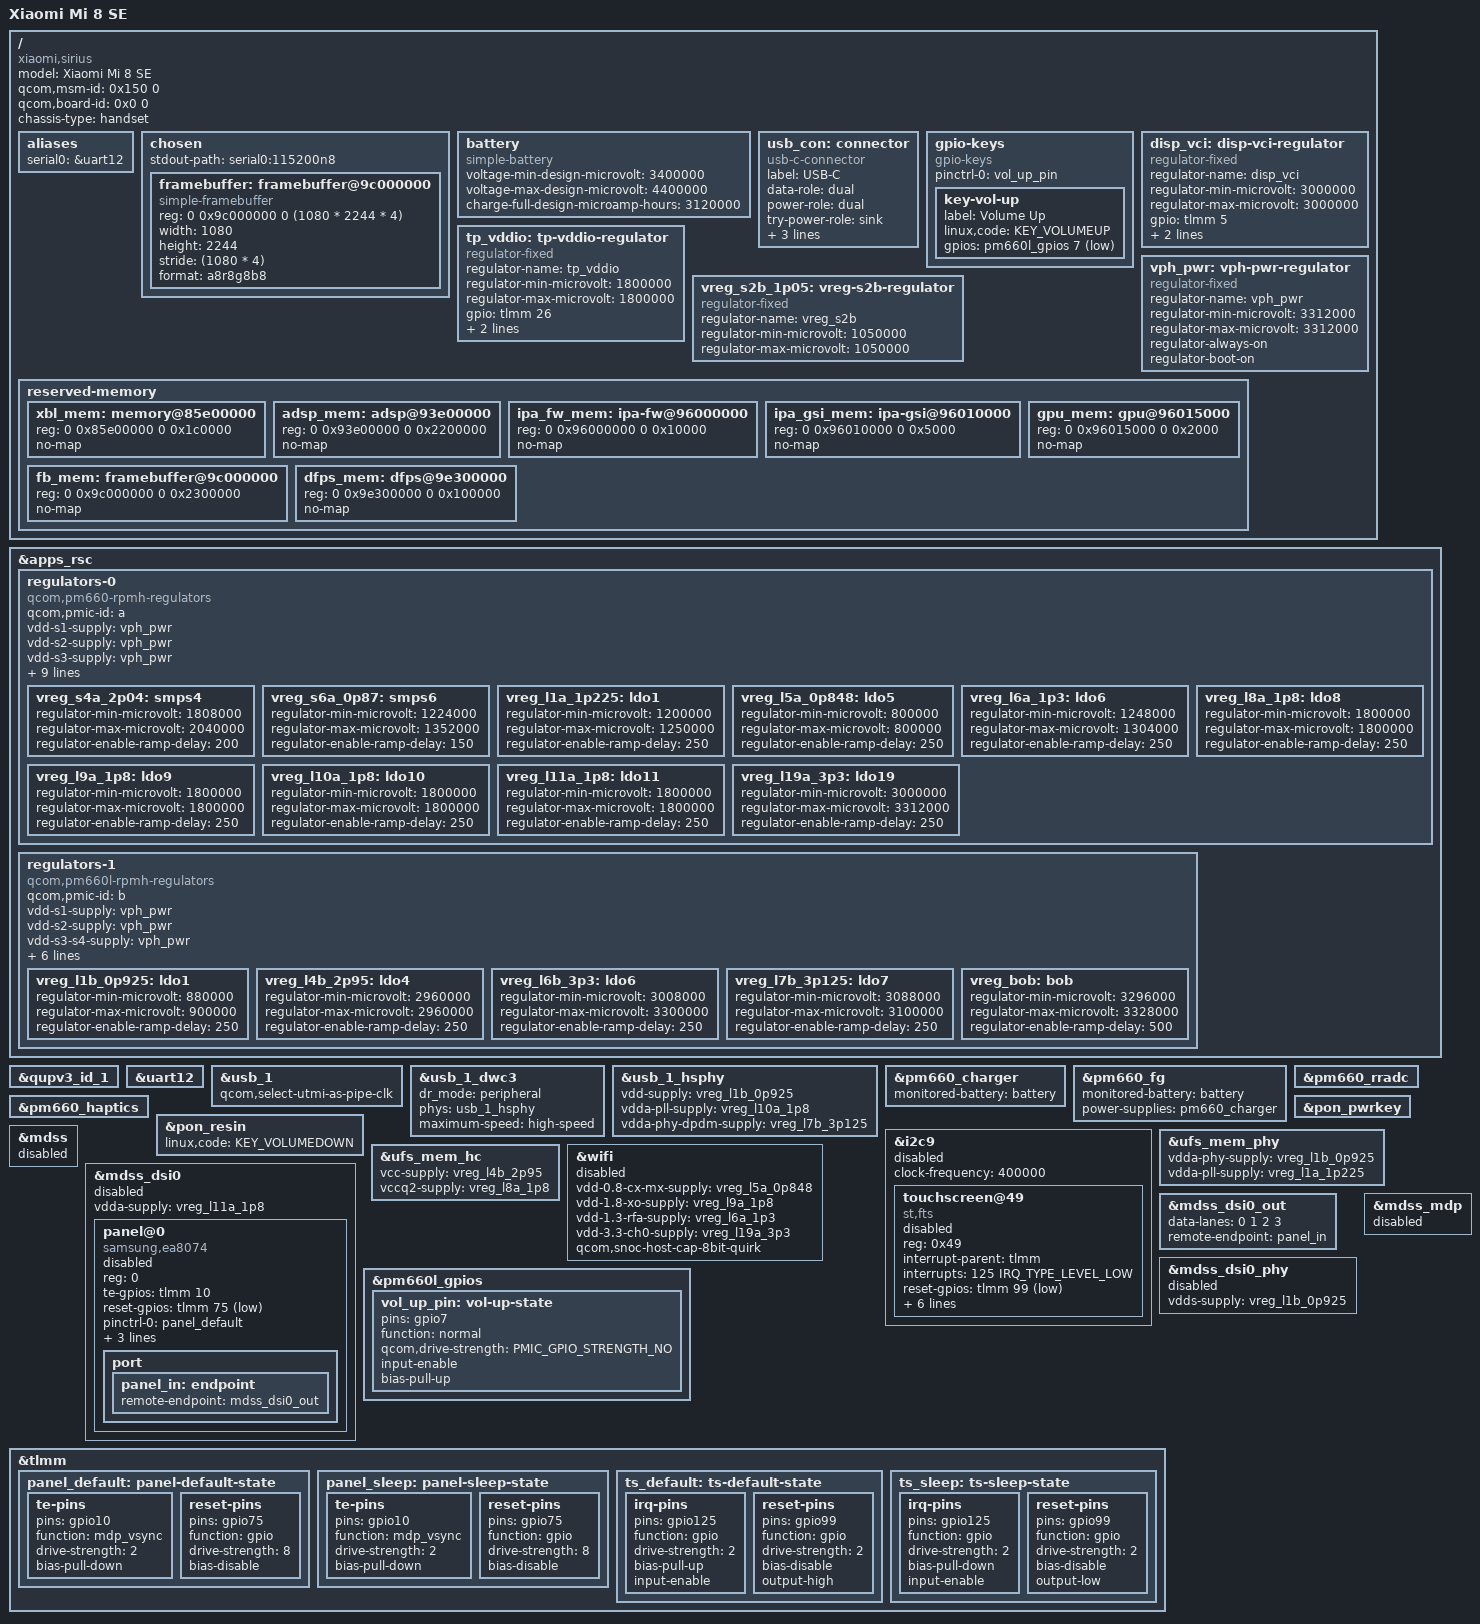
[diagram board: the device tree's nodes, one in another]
// SPDX-License-Identifier: GPL-2.0
/*
 * Xiaomi Mi 8 SE (sirius / xmsirius), SDM710.
 *
 * First board pass: reserved-memory from this unit's live Android DT
 * (2026-08-28), debug UART at 0xA90000, USB2 gadget on a600000.dwc3,
 * PM660 charger + fuel gauge, USB-C connector from this unit's PD caps.
 * No pyxis USB-ID GPIO 38.
 *
 * SMB1355 sits on i2c@a88000 (mainline i2c10) as the Android parallel
 * charger. The shared sdm670-mainline tree has no SMB1355 driver;
 * do not invent a node for it.
 *
 * Display: simple-framebuffer for first boot. Samsung EA8074
 * 1080x2244 command-mode panel driver is in kernel/panel-samsung-ea8074.c
 * (this phone's Android init, not the Mi 8 2248 notch sequence).
 * MDSS/DSI nodes stay disabled until USB enumerates — do not bind
 * samsung,ea8076.
 *
 * UFS uses this phone's Xiaomi 710 supplies (VCCQ2 is PM660 L8 at
 * 1.8 V, not pyxis PM660L L8 at 3.3 V). No UFS reset GPIO in the
 * live Android DT.
 *
 * Wi-Fi supplies are filled; &wifi and remoteproc stay disabled
 * until USB enumerates on hardware. Do not use pyxis board-2.bin.
 */

/dts-v1/;

#include <dt-bindings/gpio/gpio.h>
#include <dt-bindings/input/input.h>
#include <dt-bindings/interrupt-controller/irq.h>
#include <dt-bindings/pinctrl/qcom,pmic-gpio.h>
#include <dt-bindings/power/qcom-rpmpd.h>
#include <dt-bindings/usb/pd.h>
#include "sdm710.dtsi"
#include "pm660.dtsi"
#include "pm660l.dtsi"

/delete-node/ &xbl_mem;
/delete-node/ &adsp_mem;
/delete-node/ &ipa_fw_mem;
/delete-node/ &ipa_gsi_mem;
/delete-node/ &gpu_mem;

/ {
	model = "Xiaomi Mi 8 SE";
	compatible = "xiaomi,sirius", "qcom,sdm710";
	/* Must match this phone's stock boot.img base DTB (ABL match),
	 * not the live Android tree after dtbo overlays (0x168 / 0x20).
	 */
	qcom,msm-id = <0x150 0>;
	qcom,board-id = <0x0 0>;
	chassis-type = "handset";

	aliases {
		serial0 = &uart12;
	};

	chosen {
		stdout-path = "serial0:115200n8";
		#address-cells = <2>;
		#size-cells = <2>;
		ranges;

		/* Live Android 2026-08-28: Physical size 1080x2244.
		 * Only useful if firmware left a splash in fb_mem.
		 * Keep console on serial0 — do not switch stdout here.
		 */
		framebuffer: framebuffer@9c000000 {
			compatible = "simple-framebuffer";
			reg = <0 0x9c000000 0 (1080 * 2244 * 4)>;
			width = <1080>;
			height = <2244>;
			stride = <(1080 * 4)>;
			format = "a8r8g8b8";
		};
	};

	/* Live Android sysfs 2026-08-28: charge_full_design=3120000,
	 * voltage_max=4400000, bms BATTERY_TYPE=e2_atl, Li-poly.
	 * Fuel-gauge cutoff in the live DT is 3400 mV.
	 */
	battery: battery {
		compatible = "simple-battery";
		voltage-min-design-microvolt = <3400000>;
		voltage-max-design-microvolt = <4400000>;
		charge-full-design-microamp-hours = <3120000>;
	};

	/*
	 * Type-C receptacle on this phone. CC / PD silicon (live Android):
	 *   usb-chgpth@1300  interrupt type-c-change
	 *   usb-pdphy@1700   compatible qcom,qpnp-pdphy
	 *                    irqs sig-tx/rx, msg-tx/rx, msg-tx-failed,
	 *                    msg-tx-discarded, msg-rx-discarded
	 *   vdd-pdphy        PM660L L7 (same rail as vreg_l7b_3p125)
	 *   vbus / vconn     smb2-vbus / smb2-vconn on qpnp-smb2
	 *   sink caps        5 V / 3 A and 9 V / 3 A
	 *
	 * Shared sdm670-v7.1.3 TYPEC_QCOM_PMIC only matches pm8150b.
	 * Do not bind that compatible onto PM660, and do not add
	 * usb-role-switch on dwc3 until a real PM660 TCPM exists
	 * (gadget enumeration would wait forever).
	 */
	usb_con: connector {
		compatible = "usb-c-connector";
		label = "USB-C";
		data-role = "dual";
		power-role = "dual";
		try-power-role = "sink";
		sink-pdos = <PDO_FIXED(5000, 3000, PDO_FIXED_USB_COMM)
			     PDO_FIXED(9000, 3000, 0)>;
		op-sink-microwatt = <15000000>;
	};

	/* Same PM660L GPIO 7 as this unit's Android gpio-keys. */
	gpio-keys {
		compatible = "gpio-keys";
		pinctrl-names = "default";
		pinctrl-0 = <&vol_up_pin>;

		key-vol-up {
			label = "Volume Up";
			linux,code = <KEY_VOLUMEUP>;
			gpios = <&pm660l_gpios 7 GPIO_ACTIVE_LOW>;
		};
	};

	/* Panel VCI: TLMM GPIO 5, Android disp_vci_vreg, 3.0 V. */
	disp_vci: disp-vci-regulator {
		compatible = "regulator-fixed";
		regulator-name = "disp_vci";
		regulator-min-microvolt = <3000000>;
		regulator-max-microvolt = <3000000>;
		gpio = <&tlmm 5 GPIO_ACTIVE_HIGH>;
		enable-active-high;
		startup-delay-us = <10000>;
	};

	/* Touch IO: TLMM GPIO 26, Android tp_vddio_vreg. */
	tp_vddio: tp-vddio-regulator {
		compatible = "regulator-fixed";
		regulator-name = "tp_vddio";
		regulator-min-microvolt = <1800000>;
		regulator-max-microvolt = <1800000>;
		gpio = <&tlmm 26 GPIO_ACTIVE_HIGH>;
		enable-active-high;
		startup-delay-us = <4000>;
	};

	vph_pwr: vph-pwr-regulator {
		compatible = "regulator-fixed";
		regulator-name = "vph_pwr";
		regulator-min-microvolt = <3312000>;
		regulator-max-microvolt = <3312000>;
		regulator-always-on;
		regulator-boot-on;
	};

	/* Parent of PM660L L1 / USB PHY vdd. Same PMIC family as pyxis. */
	vreg_s2b_1p05: vreg-s2b-regulator {
		compatible = "regulator-fixed";
		regulator-name = "vreg_s2b";
		regulator-min-microvolt = <1050000>;
		regulator-max-microvolt = <1050000>;
	};

	reserved-memory {
		#address-cells = <2>;
		#size-cells = <2>;

		/*
		 * hyp_mem, camera_mem, and mpss already exist in sdm670.dtsi
		 * at this phone's live addresses. Do not redeclare those
		 * labels. Only replace nodes whose size or base differs.
		 */
		xbl_mem: memory@85e00000 {
			reg = <0 0x85e00000 0 0x1c0000>;
			no-map;
		};

		/*
		 * Android's removed@85fc0000 is the same physical hole as
		 * SoC aop / cmd-db / smem / tz (ends at 0x88f00000 = rmtfs).
		 * Do not re-add it, and do not delete &rmtfs_mem: this
		 * phone does not relocate rmtfs the way pyxis does.
		 * wlan_msa / cdsp / mba already match the SoC file.
		 */
		adsp_mem: adsp@93e00000 {
			reg = <0 0x93e00000 0 0x2200000>;
			no-map;
		};

		ipa_fw_mem: ipa-fw@96000000 {
			reg = <0 0x96000000 0 0x10000>;
			no-map;
		};

		ipa_gsi_mem: ipa-gsi@96010000 {
			reg = <0 0x96010000 0 0x5000>;
			no-map;
		};

		gpu_mem: gpu@96015000 {
			reg = <0 0x96015000 0 0x2000>;
			no-map;
		};

		fb_mem: framebuffer@9c000000 {
			reg = <0 0x9c000000 0 0x2300000>;
			no-map;
		};

		/* Live Android 2026-08-28: between splash and SoC qseecom. */
		dfps_mem: dfps@9e300000 {
			reg = <0 0x9e300000 0 0x100000>;
			no-map;
		};
	};
};

/* RPMH rails needed so the USB PHY supplies exist. Voltages follow
 * the shared PM660 / PM660L map used on pyxis; unused consumers stay off.
 */
&apps_rsc {
	regulators-0 {
		compatible = "qcom,pm660-rpmh-regulators";
		qcom,pmic-id = "a";

		vdd-s1-supply = <&vph_pwr>;
		vdd-s2-supply = <&vph_pwr>;
		vdd-s3-supply = <&vph_pwr>;
		vdd-s4-supply = <&vph_pwr>;
		vdd-s5-supply = <&vph_pwr>;
		vdd-s6-supply = <&vph_pwr>;

		vdd-l1-l6-l7-supply = <&vreg_s6a_0p87>;
		vdd-l2-l3-supply = <&vreg_s2b_1p05>;
		vdd-l5-supply = <&vreg_s2b_1p05>;
		vdd-l8-l9-l10-l11-l12-l13-l14-supply = <&vreg_s4a_2p04>;
		vdd-l15-l16-l17-l18-l19-supply = <&vreg_bob>;

		vreg_s4a_2p04: smps4 {
			regulator-min-microvolt = <1808000>;
			regulator-max-microvolt = <2040000>;
			regulator-enable-ramp-delay = <200>;
		};

		vreg_s6a_0p87: smps6 {
			regulator-min-microvolt = <1224000>;
			regulator-max-microvolt = <1352000>;
			regulator-enable-ramp-delay = <150>;
		};

		vreg_l1a_1p225: ldo1 {
			regulator-min-microvolt = <1200000>;
			regulator-max-microvolt = <1250000>;
			regulator-enable-ramp-delay = <250>;
		};

		vreg_l5a_0p848: ldo5 {
			regulator-min-microvolt = <800000>;
			regulator-max-microvolt = <800000>;
			regulator-enable-ramp-delay = <250>;
		};

		vreg_l6a_1p3: ldo6 {
			regulator-min-microvolt = <1248000>;
			regulator-max-microvolt = <1304000>;
			regulator-enable-ramp-delay = <250>;
		};

		vreg_l8a_1p8: ldo8 {
			regulator-min-microvolt = <1800000>;
			regulator-max-microvolt = <1800000>;
			regulator-enable-ramp-delay = <250>;
		};

		vreg_l9a_1p8: ldo9 {
			regulator-min-microvolt = <1800000>;
			regulator-max-microvolt = <1800000>;
			regulator-enable-ramp-delay = <250>;
		};

		vreg_l10a_1p8: ldo10 {
			regulator-min-microvolt = <1800000>;
			regulator-max-microvolt = <1800000>;
			regulator-enable-ramp-delay = <250>;
		};

		vreg_l11a_1p8: ldo11 {
			regulator-min-microvolt = <1800000>;
			regulator-max-microvolt = <1800000>;
			regulator-enable-ramp-delay = <250>;
		};

		vreg_l19a_3p3: ldo19 {
			regulator-min-microvolt = <3000000>;
			regulator-max-microvolt = <3312000>;
			regulator-enable-ramp-delay = <250>;
		};
	};

	regulators-1 {
		compatible = "qcom,pm660l-rpmh-regulators";
		qcom,pmic-id = "b";

		vdd-s1-supply = <&vph_pwr>;
		vdd-s2-supply = <&vph_pwr>;
		vdd-s3-s4-supply = <&vph_pwr>;
		vdd-s5-supply = <&vph_pwr>;

		vdd-l1-l9-l10-supply = <&vreg_s2b_1p05>;
		vdd-l2-supply = <&vreg_bob>;
		vdd-l3-l5-l7-l8-supply = <&vreg_bob>;
		vdd-l4-l6-supply = <&vreg_bob>;
		vdd-bob-supply = <&vph_pwr>;

		vreg_l1b_0p925: ldo1 {
			regulator-min-microvolt = <880000>;
			regulator-max-microvolt = <900000>;
			regulator-enable-ramp-delay = <250>;
		};

		vreg_l4b_2p95: ldo4 {
			regulator-min-microvolt = <2960000>;
			regulator-max-microvolt = <2960000>;
			regulator-enable-ramp-delay = <250>;
		};

		vreg_l6b_3p3: ldo6 {
			regulator-min-microvolt = <3008000>;
			regulator-max-microvolt = <3300000>;
			regulator-enable-ramp-delay = <250>;
		};

		vreg_l7b_3p125: ldo7 {
			regulator-min-microvolt = <3088000>;
			regulator-max-microvolt = <3100000>;
			regulator-enable-ramp-delay = <250>;
		};

		vreg_bob: bob {
			regulator-min-microvolt = <3296000>;
			regulator-max-microvolt = <3328000>;
			regulator-enable-ramp-delay = <500>;
		};
	};
};

&qupv3_id_1 {
	status = "okay";
};

/* earlycon=msm_geni_serial,0xA90000 on this unit */
&uart12 {
	status = "okay";
};

/* USB2 only — Android DT sets dwc3 maximum-speed = high-speed. */
&usb_1 {
	status = "okay";
	qcom,select-utmi-as-pipe-clk;
};

&usb_1_dwc3 {
	dr_mode = "peripheral";
	phys = <&usb_1_hsphy>;
	phy-names = "usb2-phy";
	maximum-speed = "high-speed";

	/delete-property/ snps,dis_u2_susphy_quirk;
	/delete-property/ snps,dis_enblslpm_quirk;
};

&usb_1_hsphy {
	status = "okay";
	vdd-supply = <&vreg_l1b_0p925>;
	vdda-pll-supply = <&vreg_l10a_1p8>;
	vdda-phy-dpdm-supply = <&vreg_l7b_3p125>;
};

/* Mainline qcom,pm660-charger / qcom,pmi8998-fg. Do not copy
 * Android qpnp-smb2 properties (fcc-max-ua and friends).
 */
&pm660_charger {
	monitored-battery = <&battery>;
	status = "okay";
};

&pm660_fg {
	monitored-battery = <&battery>;
	power-supplies = <&pm660_charger>;
	status = "okay";
};

&pm660_rradc {
	status = "okay";
};

&pm660_haptics {
	status = "okay";
};

&pon_pwrkey {
	status = "okay";
};

&pon_resin {
	linux,code = <KEY_VOLUMEDOWN>;
	status = "okay";
};

/* Touch: live compatible st,fts @ i2c 0xa84000 addr 0x49.
 * Keep the bus off until USB works and st_fts_v521.ftb is packaged.
 */
&i2c9 {
	status = "disabled";
	clock-frequency = <400000>;

	touchscreen@49 {
		compatible = "st,fts";
		reg = <0x49>;
		interrupt-parent = <&tlmm>;
		interrupts = <125 IRQ_TYPE_LEVEL_LOW>;
		reset-gpios = <&tlmm 99 GPIO_ACTIVE_LOW>;
		pinctrl-names = "default", "sleep";
		pinctrl-0 = <&ts_default>;
		pinctrl-1 = <&ts_sleep>;
		vdd-supply = <&tp_vddio>;
		avdd-supply = <&vreg_l6b_3p3>;
		touchscreen-size-x = <1080>;
		touchscreen-size-y = <2244>;
		/* No panel and no st_fts_v521.ftb in the firmware package.
		 * Probe can stall first USB bring-up. Enable after USB works.
		 */
		status = "disabled";
	};
};

/*
 * Speaker: live dmesg shows TI TAS2557 at i2c 2-004c
 * (Android &qupv3_se7_i2c, reset GPIO 95, irq GPIO 96).
 * kernel/tas2557.c is staged into the shared kernel package.
 * Do not add an I2C node or enable LPASS until USB works and
 * tas2557_uCDSP.bin / tas2557_cal.bin are packaged.
 */

/* Xiaomi SDM710 common: phy L1B + L1A, VCC L4B 2.96 V, VCCQ2 L8A 1.8 V.
 * This unit's live DT has no UFS reset GPIO — do not copy pyxis GPIO 150.
 */
&ufs_mem_phy {
	status = "okay";
	vdda-phy-supply = <&vreg_l1b_0p925>;
	vdda-pll-supply = <&vreg_l1a_1p225>;
};

&ufs_mem_hc {
	status = "okay";
	vcc-supply = <&vreg_l4b_2p95>;
	vccq2-supply = <&vreg_l8a_1p8>;
};

/*
 * WCN399x rails (this phone reports WCN3998). Stay disabled:
 * ath10k_snoc needs remoteproc + this unit's wlanmdsp/bdwlan.
 * Enabling it before USB works can power the phone off (pyxis
 * commented board-2.bin for that reason).
 */
&wifi {
	vdd-0.8-cx-mx-supply = <&vreg_l5a_0p848>;
	vdd-1.8-xo-supply = <&vreg_l9a_1p8>;
	vdd-1.3-rfa-supply = <&vreg_l6a_1p3>;
	vdd-3.3-ch0-supply = <&vreg_l19a_3p3>;
	qcom,snoc-host-cap-8bit-quirk;
	status = "disabled";
};

/*
 * Samsung EA8074 1080x2244 command-mode. Driver lives in
 * kernel/panel-samsung-ea8074.c (this phone's Android init).
 * Keep MDSS / DSI / panel off until USB enumerates — turning
 * the display subsystem on for first boot can hang.
 * Do not bind samsung,ea8076.
 */
&mdss {
	status = "disabled";
};

&mdss_dsi0 {
	status = "disabled";
	vdda-supply = <&vreg_l11a_1p8>;

	panel@0 {
		compatible = "samsung,ea8074";
		reg = <0>;
		status = "disabled";

		/* Android te-gpio flag 0; reset sequence is physical <0 2>, <1 11>. */
		te-gpios = <&tlmm 10 GPIO_ACTIVE_HIGH>;
		reset-gpios = <&tlmm 75 GPIO_ACTIVE_LOW>;

		pinctrl-names = "default", "sleep";
		pinctrl-0 = <&panel_default>;
		pinctrl-1 = <&panel_sleep>;

		vddio-supply = <&vreg_l11a_1p8>;
		vci-supply = <&disp_vci>;

		port {
			panel_in: endpoint {
				remote-endpoint = <&mdss_dsi0_out>;
			};
		};
	};
};

&mdss_dsi0_out {
	data-lanes = <0 1 2 3>;
	remote-endpoint = <&panel_in>;
};

&mdss_dsi0_phy {
	status = "disabled";
	vdds-supply = <&vreg_l1b_0p925>;
};

&mdss_mdp {
	status = "disabled";
};

&pm660l_gpios {
	vol_up_pin: vol-up-state {
		pins = "gpio7";
		function = "normal";
		qcom,drive-strength = <PMIC_GPIO_STRENGTH_NO>;
		input-enable;
		bias-pull-up;
	};
};

&tlmm {
	panel_default: panel-default-state {
		te-pins {
			pins = "gpio10";
			function = "mdp_vsync";
			drive-strength = <2>;
			bias-pull-down;
		};

		reset-pins {
			pins = "gpio75";
			function = "gpio";
			drive-strength = <8>;
			bias-disable;
		};
	};

	panel_sleep: panel-sleep-state {
		te-pins {
			pins = "gpio10";
			function = "mdp_vsync";
			drive-strength = <2>;
			bias-pull-down;
		};

		reset-pins {
			pins = "gpio75";
			function = "gpio";
			drive-strength = <8>;
			bias-disable;
		};
	};

	ts_default: ts-default-state {
		irq-pins {
			pins = "gpio125";
			function = "gpio";
			drive-strength = <2>;
			bias-pull-up;
			input-enable;
		};

		reset-pins {
			pins = "gpio99";
			function = "gpio";
			drive-strength = <2>;
			bias-disable;
			output-high;
		};
	};

	ts_sleep: ts-sleep-state {
		irq-pins {
			pins = "gpio125";
			function = "gpio";
			drive-strength = <2>;
			bias-pull-down;
			input-enable;
		};

		reset-pins {
			pins = "gpio99";
			function = "gpio";
			drive-strength = <2>;
			bias-disable;
			output-low;
		};
	};
};
